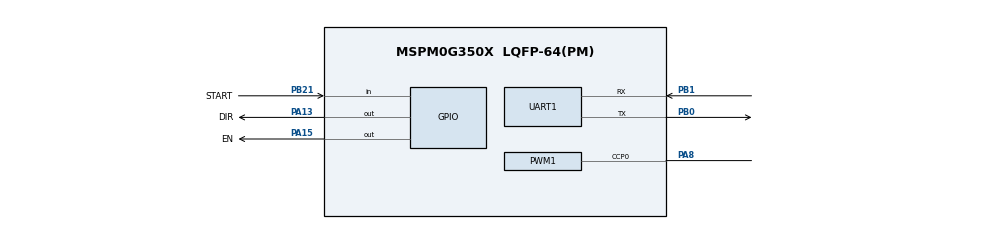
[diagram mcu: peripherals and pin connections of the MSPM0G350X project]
/**
 * @cliArgs --device "MSPM0G350X" --part "Default" --package "LQFP-64(PM)" --product "mspm0_sdk@2.02.00.05"
 * @versions {"tool":"1.21.1+3772"}
 */

/**
 * Import the modules used in this configuration.
 */
const GPIO   = scripting.addModule("/ti/driverlib/GPIO", {}, false);
const GPIO1  = GPIO.addInstance();
const GPIO2  = GPIO.addInstance();
const I2C    = scripting.addModule("/ti/driverlib/I2C", {}, false);
const I2C1   = I2C.addInstance();
const PWM    = scripting.addModule("/ti/driverlib/PWM", {}, false);
const PWM1   = PWM.addInstance();
const SYSCTL = scripting.addModule("/ti/driverlib/SYSCTL");
const UART   = scripting.addModule("/ti/driverlib/UART", {}, false);
const UART1  = UART.addInstance();
const WWDT   = scripting.addModule("/ti/driverlib/WWDT", {}, false);
const WWDT1  = WWDT.addInstance();

/**
 * Write custom configuration values to the imported modules.
 */
GPIO1.$name                         = "TMC2208";
GPIO1.port                          = "PORTA";
GPIO1.associatedPins.create(2);
GPIO1.associatedPins[0].$name       = "DIR";
GPIO1.associatedPins[0].pin.$assign = "PA13";
GPIO1.associatedPins[1].$name       = "EN";
GPIO1.associatedPins[1].pin.$assign = "PA15";
GPIO1.associatedPins[1].initialValue = "SET";

/* PB21 button: active low, used only for the pre-run 65 mm balance setup. */
GPIO2.$name                              = "KEY";
GPIO2.port                               = "PORTB";
GPIO2.associatedPins[0].$name            = "START";
GPIO2.associatedPins[0].direction        = "INPUT";
GPIO2.associatedPins[0].internalResistor = "PULL_UP";
GPIO2.associatedPins[0].pin.$assign      = "PB21";

const Board = scripting.addModule("/ti/driverlib/Board", {}, false);

I2C1.$name                           = "I2C_0";
I2C1.basicEnableController           = true;
I2C1.basicControllerStandardBusSpeed = "Fast";
I2C1.sdaPinConfig.$name              = "ti_driverlib_gpio_GPIOPinGeneric2";
I2C1.sclPinConfig.$name              = "ti_driverlib_gpio_GPIOPinGeneric3";

PWM1.clockDivider                       = 8;
PWM1.timerStartTimer                    = false;
PWM1.ccIndex                            = [0];
PWM1.$name                              = "STEP";
PWM1.peripheral.$assign                 = "TIMA0";
PWM1.peripheral.ccp0Pin.$assign         = "PA8";
PWM1.PWM_CHANNEL_0.$name                = "ti_driverlib_pwm_PWMTimerCC0";
PWM1.ccp0PinConfig.direction            = scripting.forceWrite("OUTPUT");
PWM1.ccp0PinConfig.hideOutputInversion  = scripting.forceWrite(false);
PWM1.ccp0PinConfig.onlyInternalResistor = scripting.forceWrite(false);
PWM1.ccp0PinConfig.passedPeripheralType = scripting.forceWrite("Digital");
PWM1.ccp0PinConfig.$name                = "ti_driverlib_gpio_GPIOPinGeneric4";

SYSCTL.forceDefaultClkConfig = true;

UART1.$name                    = "UART_0";
UART1.targetBaudRate           = 115200;
UART1.uartClkDiv               = "8";
UART1.enabledInterrupts        = ["RX"];
UART1.peripheral.$assign       = "UART0";
UART1.peripheral.rxPin.$assign = "PB1";
UART1.peripheral.txPin.$assign = "PB0";
UART1.txPinConfig.$name        = "ti_driverlib_gpio_GPIOPinGeneric0";
UART1.rxPinConfig.$name        = "ti_driverlib_gpio_GPIOPinGeneric1";

/* LFCLK window watchdog: window 0 has no closed period, main loop may feed safely. */
WWDT1.$name               = "WWDT0";
WWDT1.clockDivider        = "2";
WWDT1.periodCount         = "15";
WWDT1.sleepMode           = true;
WWDT1.window0ClosedPeriod = "0";

/**
 * Pinmux solution for unlocked pins/peripherals. This ensures that minor changes to the automatic solver in a future
 * version of the tool will not impact the pinmux you originally saw.  These lines can be completely deleted in order to
 * re-solve from scratch.
 */
Board.peripheral.$suggestSolution          = "DEBUGSS";
Board.peripheral.swclkPin.$suggestSolution = "PA20";
Board.peripheral.swdioPin.$suggestSolution = "PA19";
I2C1.peripheral.$suggestSolution           = "I2C0";
I2C1.peripheral.sdaPin.$suggestSolution    = "PA0";
I2C1.peripheral.sclPin.$suggestSolution    = "PA1";
SYSCTL.peripheral.$suggestSolution         = "SYSCTL";
WWDT1.peripheral.$suggestSolution          = "WWDT0";
